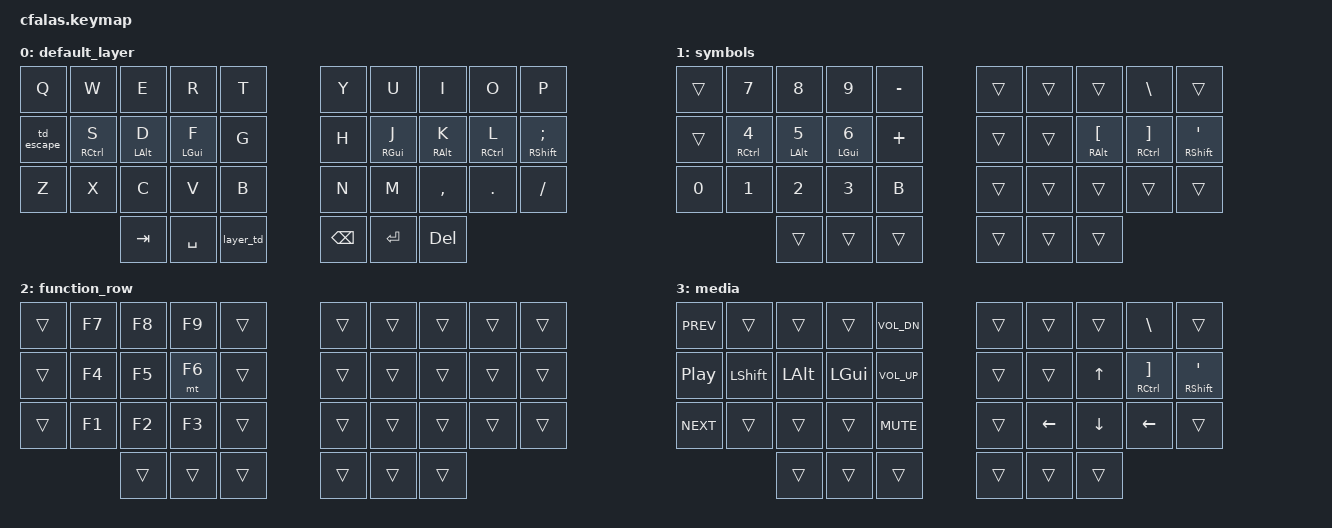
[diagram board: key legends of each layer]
#include <behaviors.dtsi>
#include <dt-bindings/zmk/keys.h>

#define DEFAULT 0
#define SYM 1
#define FUNCTION 2
#define MEDIA 3

/ {
    behaviors {
        td_escape: td_escape {
            compatible = "zmk,behavior-tap-dance";
            label = "TD_ESCAPE";
            #binding-cells = <0>;
            tapping-term-ms = <200>;
            bindings = <&mt LSHIFT A>, <&kp ESC>;
        };
        layer_td: layer_td {
            compatible = "zmk,behavior-tap-dance";
            label = "LAYER_TD";
            #binding-cells = <0>;
            tapping-term-ms = <200>;
            bindings = <&mo SYM>, <&mo MEDIA>; //, <&tog MOUSE>;
        };
    };

    keymap {
        compatible = "zmk,keymap";

        default_layer {
            bindings = <
    &kp Q      &kp W          &kp E       &kp R       &kp T                            &kp Y     &kp U        &kp I       &kp O       &kp P   
    &td_escape &mt RCTRL S    &mt LALT D  &mt LGUI F  &kp G                            &kp H     &mt RGUI J   &mt RALT K  &mt RCTRL L &mt RSHIFT SEMI
    &kp Z      &kp X          &kp C       &kp V       &kp B                            &kp N     &kp M        &kp COMMA   &kp DOT     &kp FSLH
                                        &kp TAB    &kp SPACE &layer_td    &kp BSPC   &kp RET   &kp DEL 
            >;
        };

        symbols {
            bindings = <
    &trans   &kp N7         &kp N8      &kp N9      &kp MINUS                        &trans    &trans   &trans          &kp BSLH        &trans   
    &trans   &mt RCTRL N4   &mt LALT N5 &mt LGUI N6 &kp PLUS                         &trans    &trans   &mt RALT LBKT   &mt RCTRL RBKT  &mt RSHIFT SQT
    &kp N0   &kp N1         &kp N2      &kp N3      &kp B                            &trans    &trans   &trans          &trans          &trans
                                        &trans      &trans &trans             &trans &trans    &trans 
            >;
        };
        function_row {
            bindings = <
    &trans   &kp F7   &kp F8    &kp F9      &trans                              &trans    &trans   &trans   &trans     &trans
    &trans   &kp F4   &kp F5    &mt F6      &trans                              &trans    &trans   &trans   &trans     &trans
    &trans   &kp F1   &kp F2    &kp F3      &trans                              &trans    &trans   &trans   &trans     &trans
                                &trans      &trans     &trans         &trans    &trans    &trans 
            >;
        };
        media {
            bindings = <
    &kp C_PREV   &trans         &trans      &trans      &kp C_VOL_DN                           &trans    &trans     &trans      &kp BSLH        &trans   
    &kp C_PP     &kp LSHIFT     &kp LALT    &kp LGUI    &kp C_VOL_UP                           &trans    &trans     &kp UP      &mt RCTRL RBKT  &mt RSHIFT SQT
    &kp C_NEXT   &trans         &trans      &trans      &kp C_MUTE                             &trans    &kp LEFT   &kp DOWN    &kp LEFT        &trans
                                            &trans      &trans       &trans             &trans &trans    &trans 
            >;
        };
    };
};
